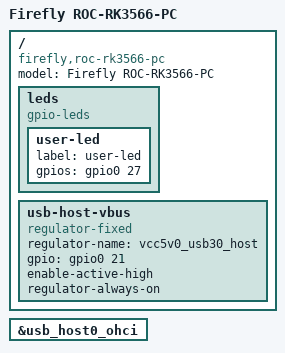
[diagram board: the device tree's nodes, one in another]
/dts-v1/;

#include "rk356x.dtsi"

/ {
	model = "Firefly ROC-RK3566-PC";
	compatible = "firefly,roc-rk3566-pc", "rockchip,rk3566";

	leds {
		compatible = "gpio-leds";
		user-led {
			label = "user-led";
			gpios = <&gpio0 27 0>;
		};
	};

	usb-host-vbus {
		compatible = "regulator-fixed";
		regulator-name = "vcc5v0_usb30_host";
		gpio = <&gpio0 21 0>;
		enable-active-high;
		regulator-always-on;
	};
};

&usb_host0_ohci {
	status = "okay";
};
